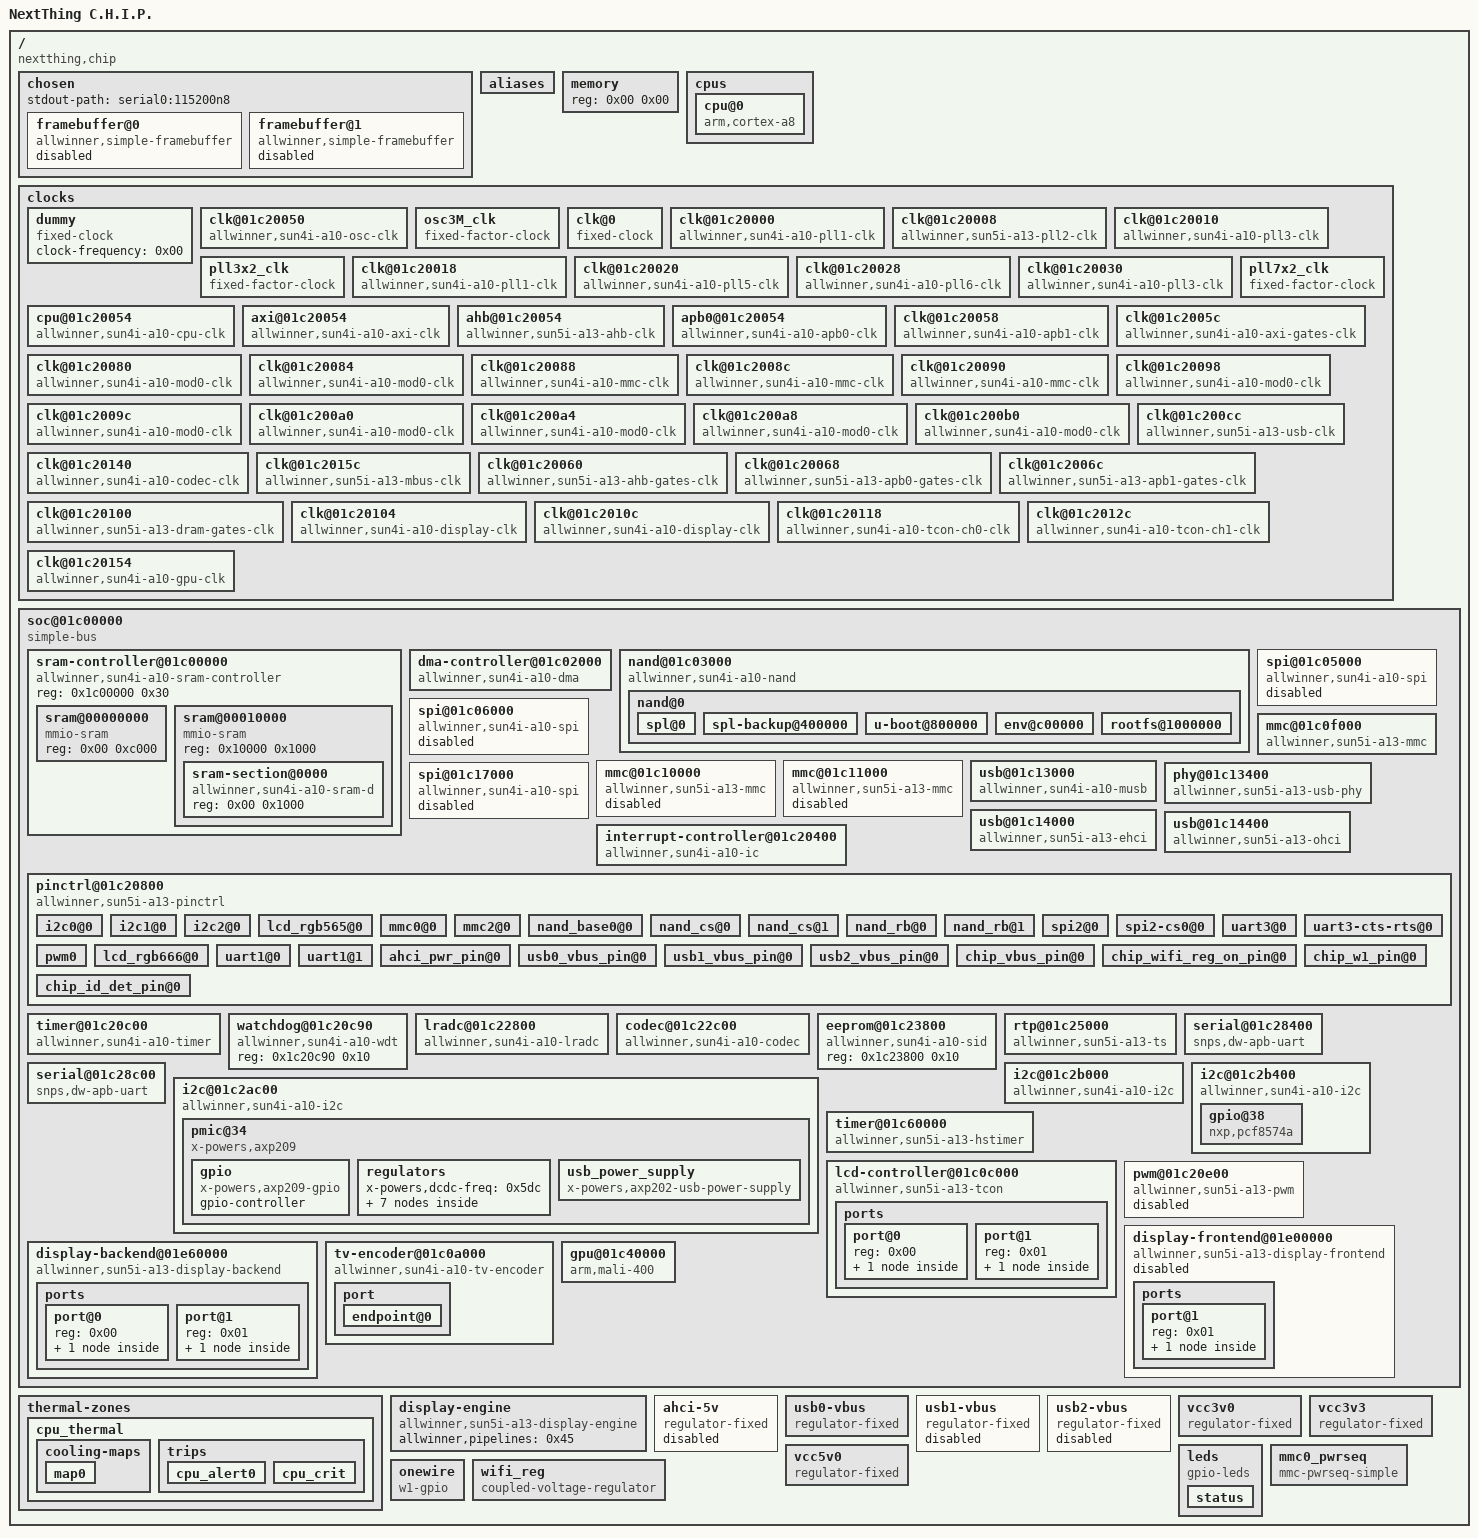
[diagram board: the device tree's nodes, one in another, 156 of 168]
/dts-v1/;

/ {
	#address-cells = <0x01>;
	#size-cells = <0x01>;
	interrupt-parent = <0x01>;
	model = "NextThing C.H.I.P.";
	compatible = "nextthing,chip", "allwinner,sun5i-r8";

	chosen {
		#address-cells = <0x01>;
		#size-cells = <0x01>;
		ranges;
		stdout-path = "serial0:115200n8";

		framebuffer@0 {
			compatible = "allwinner,simple-framebuffer", "simple-framebuffer";
			allwinner,pipeline = "de_be0-lcd0";
			clocks = <0x02 0x24 0x02 0x2c 0x03 0x04 0x05 0x1a>;
			status = "disabled";
		};

		framebuffer@1 {
			compatible = "allwinner,simple-framebuffer", "simple-framebuffer";
			allwinner,pipeline = "de_be0-lcd0-tve0";
			clocks = <0x02 0x22 0x02 0x24 0x02 0x2c 0x03 0x06 0x05 0x1a>;
			status = "disabled";
		};
	};

	aliases {
		i2c0 = "/soc@01c00000/i2c@01c2ac00";
		i2c1 = "/soc@01c00000/i2c@01c2b000";
		i2c2 = "/soc@01c00000/i2c@01c2b400";
		serial0 = "/soc@01c00000/serial@01c28400";
		serial1 = "/soc@01c00000/serial@01c28c00";
	};

	memory {
		device_type = "memory";
		reg = <0x00 0x00>;
	};

	cpus {
		#address-cells = <0x01>;
		#size-cells = <0x00>;

		cpu@0 {
			device_type = "cpu";
			compatible = "arm,cortex-a8";
			reg = <0x00>;
			clocks = <0x07>;
			clock-latency = <0x3b9b0>;
			operating-points = <0xf6180 0x155cc0 0xdea80 0x149970 0xd2f00 0x13d620 0x98580 0x124f80 0x8ca00 0x124f80 0x69780 0x124f80>;
			#cooling-cells = <0x02>;
			cooling-min-level = <0x00>;
			cooling-max-level = <0x05>;
			cpu-supply = <0x08>;
			linux,phandle = <0x44>;
			phandle = <0x44>;
		};
	};

	clocks {
		#address-cells = <0x01>;
		#size-cells = <0x01>;
		ranges;

		dummy {
			#clock-cells = <0x00>;
			compatible = "fixed-clock";
			clock-frequency = <0x00>;
			linux,phandle = <0x0f>;
			phandle = <0x0f>;
		};

		clk@01c20050 {
			#clock-cells = <0x00>;
			compatible = "allwinner,sun4i-a10-osc-clk";
			reg = <0x1c20050 0x04>;
			clock-frequency = <0x16e3600>;
			clock-output-names = "osc24M";
			linux,phandle = <0x09>;
			phandle = <0x09>;
		};

		osc3M_clk {
			compatible = "fixed-factor-clock";
			#clock-cells = <0x00>;
			clock-div = <0x08>;
			clock-mult = <0x01>;
			clocks = <0x09>;
			clock-output-names = "osc3M";
			linux,phandle = <0x0a>;
			phandle = <0x0a>;
		};

		clk@0 {
			#clock-cells = <0x00>;
			compatible = "fixed-clock";
			clock-frequency = <0x8000>;
			clock-output-names = "osc32k";
			linux,phandle = <0x0d>;
			phandle = <0x0d>;
		};

		clk@01c20000 {
			#clock-cells = <0x00>;
			compatible = "allwinner,sun4i-a10-pll1-clk";
			reg = <0x1c20000 0x04>;
			clocks = <0x09>;
			clock-output-names = "pll1";
			linux,phandle = <0x0e>;
			phandle = <0x0e>;
		};

		clk@01c20008 {
			#clock-cells = <0x01>;
			compatible = "allwinner,sun5i-a13-pll2-clk";
			reg = <0x1c20008 0x08>;
			clocks = <0x09>;
			clock-output-names = "pll2-1x", "pll2-2x", "pll2-4x", "pll2-8x";
			linux,phandle = <0x14>;
			phandle = <0x14>;
		};

		clk@01c20010 {
			#clock-cells = <0x00>;
			compatible = "allwinner,sun4i-a10-pll3-clk";
			reg = <0x1c20010 0x04>;
			clocks = <0x0a>;
			clock-output-names = "pll3";
			linux,phandle = <0x0b>;
			phandle = <0x0b>;
		};

		pll3x2_clk {
			compatible = "fixed-factor-clock";
			#clock-cells = <0x00>;
			clock-div = <0x01>;
			clock-mult = <0x02>;
			clocks = <0x0b>;
			clock-output-names = "pll3-2x";
			linux,phandle = <0x17>;
			phandle = <0x17>;
		};

		clk@01c20018 {
			#clock-cells = <0x00>;
			compatible = "allwinner,sun4i-a10-pll1-clk";
			reg = <0x1c20018 0x04>;
			clocks = <0x09>;
			clock-output-names = "pll4";
			linux,phandle = <0x19>;
			phandle = <0x19>;
		};

		clk@01c20020 {
			#clock-cells = <0x01>;
			compatible = "allwinner,sun4i-a10-pll5-clk";
			reg = <0x1c20020 0x04>;
			clocks = <0x09>;
			clock-output-names = "pll5_ddr", "pll5_other";
			linux,phandle = <0x13>;
			phandle = <0x13>;
		};

		clk@01c20028 {
			#clock-cells = <0x01>;
			compatible = "allwinner,sun4i-a10-pll6-clk";
			reg = <0x1c20028 0x04>;
			clocks = <0x09>;
			clock-output-names = "pll6_sata", "pll6_other", "pll6";
			linux,phandle = <0x11>;
			phandle = <0x11>;
		};

		clk@01c20030 {
			#clock-cells = <0x00>;
			compatible = "allwinner,sun4i-a10-pll3-clk";
			reg = <0x1c20030 0x04>;
			clocks = <0x0a>;
			clock-output-names = "pll7";
			linux,phandle = <0x0c>;
			phandle = <0x0c>;
		};

		pll7x2_clk {
			compatible = "fixed-factor-clock";
			#clock-cells = <0x00>;
			clock-div = <0x01>;
			clock-mult = <0x02>;
			clocks = <0x0c>;
			clock-output-names = "pll7-2x";
			linux,phandle = <0x18>;
			phandle = <0x18>;
		};

		cpu@01c20054 {
			#clock-cells = <0x00>;
			compatible = "allwinner,sun4i-a10-cpu-clk";
			reg = <0x1c20054 0x04>;
			clocks = <0x0d 0x09 0x0e 0x0f>;
			clock-output-names = "cpu";
			linux,phandle = <0x07>;
			phandle = <0x07>;
		};

		axi@01c20054 {
			#clock-cells = <0x00>;
			compatible = "allwinner,sun4i-a10-axi-clk";
			reg = <0x1c20054 0x04>;
			clocks = <0x07>;
			clock-output-names = "axi";
			linux,phandle = <0x10>;
			phandle = <0x10>;
		};

		ahb@01c20054 {
			#clock-cells = <0x00>;
			compatible = "allwinner,sun5i-a13-ahb-clk";
			reg = <0x1c20054 0x04>;
			clocks = <0x10 0x07 0x11 0x01>;
			clock-output-names = "ahb";
			assigned-clocks = <0x12>;
			assigned-clock-parents = <0x11 0x01>;
			linux,phandle = <0x12>;
			phandle = <0x12>;
		};

		apb0@01c20054 {
			#clock-cells = <0x00>;
			compatible = "allwinner,sun4i-a10-apb0-clk";
			reg = <0x1c20054 0x04>;
			clocks = <0x12>;
			clock-output-names = "apb0";
			linux,phandle = <0x15>;
			phandle = <0x15>;
		};

		clk@01c20058 {
			#clock-cells = <0x00>;
			compatible = "allwinner,sun4i-a10-apb1-clk";
			reg = <0x1c20058 0x04>;
			clocks = <0x09 0x11 0x01 0x0d>;
			clock-output-names = "apb1";
			linux,phandle = <0x16>;
			phandle = <0x16>;
		};

		clk@01c2005c {
			#clock-cells = <0x01>;
			compatible = "allwinner,sun4i-a10-axi-gates-clk";
			reg = <0x1c2005c 0x04>;
			clocks = <0x10>;
			clock-indices = <0x00>;
			clock-output-names = "axi_dram";
			linux,phandle = <0x4f>;
			phandle = <0x4f>;
		};

		clk@01c20080 {
			#clock-cells = <0x00>;
			compatible = "allwinner,sun4i-a10-mod0-clk";
			reg = <0x1c20080 0x04>;
			clocks = <0x09 0x11 0x01 0x13 0x01>;
			clock-output-names = "nand";
			linux,phandle = <0x1a>;
			phandle = <0x1a>;
		};

		clk@01c20084 {
			#clock-cells = <0x00>;
			compatible = "allwinner,sun4i-a10-mod0-clk";
			reg = <0x1c20084 0x04>;
			clocks = <0x09 0x11 0x01 0x13 0x01>;
			clock-output-names = "ms";
			linux,phandle = <0x50>;
			phandle = <0x50>;
		};

		clk@01c20088 {
			#clock-cells = <0x01>;
			compatible = "allwinner,sun4i-a10-mmc-clk";
			reg = <0x1c20088 0x04>;
			clocks = <0x09 0x11 0x01 0x13 0x01>;
			clock-output-names = "mmc0", "mmc0_output", "mmc0_sample";
			linux,phandle = <0x21>;
			phandle = <0x21>;
		};

		clk@01c2008c {
			#clock-cells = <0x01>;
			compatible = "allwinner,sun4i-a10-mmc-clk";
			reg = <0x1c2008c 0x04>;
			clocks = <0x09 0x11 0x01 0x13 0x01>;
			clock-output-names = "mmc1", "mmc1_output", "mmc1_sample";
			linux,phandle = <0x25>;
			phandle = <0x25>;
		};

		clk@01c20090 {
			#clock-cells = <0x01>;
			compatible = "allwinner,sun4i-a10-mmc-clk";
			reg = <0x1c20090 0x04>;
			clocks = <0x09 0x11 0x01 0x13 0x01>;
			clock-output-names = "mmc2", "mmc2_output", "mmc2_sample";
			linux,phandle = <0x26>;
			phandle = <0x26>;
		};

		clk@01c20098 {
			#clock-cells = <0x00>;
			compatible = "allwinner,sun4i-a10-mod0-clk";
			reg = <0x1c20098 0x04>;
			clocks = <0x09 0x11 0x01 0x13 0x01>;
			clock-output-names = "ts";
			linux,phandle = <0x51>;
			phandle = <0x51>;
		};

		clk@01c2009c {
			#clock-cells = <0x00>;
			compatible = "allwinner,sun4i-a10-mod0-clk";
			reg = <0x1c2009c 0x04>;
			clocks = <0x09 0x11 0x01 0x13 0x01>;
			clock-output-names = "ss";
			linux,phandle = <0x52>;
			phandle = <0x52>;
		};

		clk@01c200a0 {
			#clock-cells = <0x00>;
			compatible = "allwinner,sun4i-a10-mod0-clk";
			reg = <0x1c200a0 0x04>;
			clocks = <0x09 0x11 0x01 0x13 0x01>;
			clock-output-names = "spi0";
			linux,phandle = <0x1f>;
			phandle = <0x1f>;
		};

		clk@01c200a4 {
			#clock-cells = <0x00>;
			compatible = "allwinner,sun4i-a10-mod0-clk";
			reg = <0x1c200a4 0x04>;
			clocks = <0x09 0x11 0x01 0x13 0x01>;
			clock-output-names = "spi1";
			linux,phandle = <0x20>;
			phandle = <0x20>;
		};

		clk@01c200a8 {
			#clock-cells = <0x00>;
			compatible = "allwinner,sun4i-a10-mod0-clk";
			reg = <0x1c200a8 0x04>;
			clocks = <0x09 0x11 0x01 0x13 0x01>;
			clock-output-names = "spi2";
			linux,phandle = <0x2f>;
			phandle = <0x2f>;
		};

		clk@01c200b0 {
			#clock-cells = <0x00>;
			compatible = "allwinner,sun4i-a10-mod0-clk";
			reg = <0x1c200b0 0x04>;
			clocks = <0x09 0x11 0x01 0x13 0x01>;
			clock-output-names = "ir0";
			linux,phandle = <0x53>;
			phandle = <0x53>;
		};

		clk@01c200cc {
			#clock-cells = <0x01>;
			#reset-cells = <0x01>;
			compatible = "allwinner,sun5i-a13-usb-clk";
			reg = <0x1c200cc 0x04>;
			clocks = <0x11 0x01>;
			clock-output-names = "usb_ohci0", "usb_phy";
			linux,phandle = <0x29>;
			phandle = <0x29>;
		};

		clk@01c20140 {
			#clock-cells = <0x00>;
			compatible = "allwinner,sun4i-a10-codec-clk";
			reg = <0x1c20140 0x04>;
			clocks = <0x14 0x00>;
			clock-output-names = "codec";
			linux,phandle = <0x32>;
			phandle = <0x32>;
		};

		clk@01c2015c {
			#clock-cells = <0x00>;
			compatible = "allwinner,sun5i-a13-mbus-clk";
			reg = <0x1c2015c 0x04>;
			clocks = <0x09 0x11 0x01 0x13 0x01>;
			clock-output-names = "mbus";
			linux,phandle = <0x54>;
			phandle = <0x54>;
		};

		clk@01c20060 {
			#clock-cells = <0x01>;
			compatible = "allwinner,sun5i-a13-ahb-gates-clk";
			reg = <0x1c20060 0x08>;
			clocks = <0x12>;
			clock-indices = <0x00 0x01 0x02 0x05 0x06 0x07 0x08 0x09 0x0a 0x0d 0x0e 0x14 0x15 0x16 0x1c 0x20 0x22 0x24 0x28 0x2c 0x2e 0x33 0x34>;
			clock-output-names = "ahb_usbotg", "ahb_ehci", "ahb_ohci", "ahb_ss", "ahb_dma", "ahb_bist", "ahb_mmc0", "ahb_mmc1", "ahb_mmc2", "ahb_nand", "ahb_sdram", "ahb_spi0", "ahb_spi1", "ahb_spi2", "ahb_stimer", "ahb_ve", "ahb_tve", "ahb_lcd", "ahb_csi", "ahb_de_be", "ahb_de_fe", "ahb_iep", "ahb_mali400";
			linux,phandle = <0x02>;
			phandle = <0x02>;
		};

		clk@01c20068 {
			#clock-cells = <0x01>;
			compatible = "allwinner,sun5i-a13-apb0-gates-clk";
			reg = <0x1c20068 0x04>;
			clocks = <0x15>;
			clock-indices = <0x00 0x05 0x06>;
			clock-output-names = "apb0_codec", "apb0_pio", "apb0_ir";
			linux,phandle = <0x30>;
			phandle = <0x30>;
		};

		clk@01c2006c {
			#clock-cells = <0x01>;
			compatible = "allwinner,sun5i-a13-apb1-gates-clk";
			reg = <0x1c2006c 0x04>;
			clocks = <0x16>;
			clock-indices = <0x00 0x01 0x02 0x11 0x13>;
			clock-output-names = "apb1_i2c0", "apb1_i2c1", "apb1_i2c2", "apb1_uart1", "apb1_uart3";
			linux,phandle = <0x33>;
			phandle = <0x33>;
		};

		clk@01c20100 {
			#clock-cells = <0x01>;
			compatible = "allwinner,sun5i-a13-dram-gates-clk", "allwinner,sun4i-a10-gates-clk";
			reg = <0x1c20100 0x04>;
			clocks = <0x13 0x00>;
			clock-indices = <0x00 0x01 0x19 0x1a 0x1d 0x1f>;
			clock-output-names = "dram_ve", "dram_csi", "dram_de_fe", "dram_de_be", "dram_ace", "dram_iep";
			linux,phandle = <0x05>;
			phandle = <0x05>;
		};

		clk@01c20104 {
			#clock-cells = <0x00>;
			#reset-cells = <0x00>;
			compatible = "allwinner,sun4i-a10-display-clk";
			reg = <0x1c20104 0x04>;
			clocks = <0x0b 0x0c 0x13 0x01>;
			clock-output-names = "de-be";
			linux,phandle = <0x03>;
			phandle = <0x03>;
		};

		clk@01c2010c {
			#clock-cells = <0x00>;
			#reset-cells = <0x00>;
			compatible = "allwinner,sun4i-a10-display-clk";
			reg = <0x1c2010c 0x04>;
			clocks = <0x0b 0x0c 0x13 0x01>;
			clock-output-names = "de-fe";
			linux,phandle = <0x3c>;
			phandle = <0x3c>;
		};

		clk@01c20118 {
			#clock-cells = <0x00>;
			#reset-cells = <0x01>;
			compatible = "allwinner,sun4i-a10-tcon-ch0-clk";
			reg = <0x1c20118 0x04>;
			clocks = <0x0b 0x0c 0x17 0x18>;
			clock-output-names = "tcon-ch0-sclk";
			linux,phandle = <0x04>;
			phandle = <0x04>;
		};

		clk@01c2012c {
			#clock-cells = <0x00>;
			compatible = "allwinner,sun4i-a10-tcon-ch1-clk";
			reg = <0x1c2012c 0x04>;
			clocks = <0x0b 0x0c 0x17 0x18>;
			clock-output-names = "tcon-ch1-sclk";
			linux,phandle = <0x06>;
			phandle = <0x06>;
		};

		clk@01c20154 {
			#clock-cells = <0x00>;
			#reset-cells = <0x00>;
			compatible = "allwinner,sun4i-a10-gpu-clk";
			reg = <0x1c20154 0x04>;
			clocks = <0x0b 0x19 0x13 0x01 0x0c 0x18>;
			clock-output-names = "mali";
			linux,phandle = <0x41>;
			phandle = <0x41>;
		};
	};

	soc@01c00000 {
		compatible = "simple-bus";
		#address-cells = <0x01>;
		#size-cells = <0x01>;
		ranges;

		sram-controller@01c00000 {
			compatible = "allwinner,sun4i-a10-sram-controller";
			reg = <0x1c00000 0x30>;
			#address-cells = <0x01>;
			#size-cells = <0x01>;
			ranges;

			sram@00000000 {
				compatible = "mmio-sram";
				reg = <0x00 0xc000>;
				#address-cells = <0x01>;
				#size-cells = <0x01>;
				ranges = <0x00 0x00 0xc000>;
				linux,phandle = <0x55>;
				phandle = <0x55>;
			};

			sram@00010000 {
				compatible = "mmio-sram";
				reg = <0x10000 0x1000>;
				#address-cells = <0x01>;
				#size-cells = <0x01>;
				ranges = <0x00 0x10000 0x1000>;
				linux,phandle = <0x56>;
				phandle = <0x56>;

				sram-section@0000 {
					compatible = "allwinner,sun4i-a10-sram-d";
					reg = <0x00 0x1000>;
					status = "okay";
					linux,phandle = <0x28>;
					phandle = <0x28>;
				};
			};
		};

		dma-controller@01c02000 {
			compatible = "allwinner,sun4i-a10-dma";
			reg = <0x1c02000 0x1000>;
			interrupts = <0x1b>;
			clocks = <0x02 0x06>;
			#dma-cells = <0x02>;
			linux,phandle = <0x1e>;
			phandle = <0x1e>;
		};

		nand@01c03000 {
			compatible = "allwinner,sun4i-a10-nand";
			reg = <0x1c03000 0x1000>;
			interrupts = <0x25>;
			clocks = <0x02 0x0d 0x1a>;
			clock-names = "ahb", "mod";
			#address-cells = <0x01>;
			#size-cells = <0x00>;
			status = "okay";
			pinctrl-names = "default";
			pinctrl-0 = <0x1b 0x1c 0x1d>;
			dmas = <0x1e 0x01 0x03>;
			dma-names = "rxtx";
			linux,phandle = <0x57>;
			phandle = <0x57>;

			nand@0 {
				#address-cells = <0x02>;
				#size-cells = <0x02>;
				reg = <0x00>;
				allwinner,rb = <0x00>;
				nand-ecc-mode = "hw";

				spl@0 {
					label = "SPL";
					reg = <0x00 0x00 0x00 0x400000>;
				};

				spl-backup@400000 {
					label = "SPL.backup";
					reg = <0x00 0x400000 0x00 0x400000>;
				};

				u-boot@800000 {
					label = "U-Boot";
					reg = <0x00 0x800000 0x00 0x400000>;
				};

				env@c00000 {
					label = "env";
					reg = <0x00 0xc00000 0x00 0x400000>;
				};

				rootfs@1000000 {
					label = "rootfs";
					reg = <0x00 0x1000000 0x01 0xff000000>;
				};
			};
		};

		spi@01c05000 {
			compatible = "allwinner,sun4i-a10-spi";
			reg = <0x1c05000 0x1000>;
			interrupts = <0x0a>;
			clocks = <0x02 0x14 0x1f>;
			clock-names = "ahb", "mod";
			dmas = <0x1e 0x01 0x1b 0x1e 0x01 0x1a>;
			dma-names = "rx", "tx";
			status = "disabled";
			#address-cells = <0x01>;
			#size-cells = <0x00>;
			linux,phandle = <0x58>;
			phandle = <0x58>;
		};

		spi@01c06000 {
			compatible = "allwinner,sun4i-a10-spi";
			reg = <0x1c06000 0x1000>;
			interrupts = <0x0b>;
			clocks = <0x02 0x15 0x20>;
			clock-names = "ahb", "mod";
			dmas = <0x1e 0x01 0x09 0x1e 0x01 0x08>;
			dma-names = "rx", "tx";
			status = "disabled";
			#address-cells = <0x01>;
			#size-cells = <0x00>;
			linux,phandle = <0x59>;
			phandle = <0x59>;
		};

		mmc@01c0f000 {
			compatible = "allwinner,sun5i-a13-mmc";
			reg = <0x1c0f000 0x1000>;
			clocks = <0x02 0x08 0x21 0x00 0x21 0x01 0x21 0x02>;
			clock-names = "ahb", "mmc", "output", "sample";
			interrupts = <0x20>;
			status = "okay";
			#address-cells = <0x01>;
			#size-cells = <0x00>;
			pinctrl-names = "default";
			pinctrl-0 = <0x22>;
			vmmc-supply = <0x23>;
			mmc-pwrseq = <0x24>;
			bus-width = <0x04>;
			non-removable;
			linux,phandle = <0x5a>;
			phandle = <0x5a>;
		};

		mmc@01c10000 {
			compatible = "allwinner,sun5i-a13-mmc";
			reg = <0x1c10000 0x1000>;
			clocks = <0x02 0x09 0x25 0x00 0x25 0x01 0x25 0x02>;
			clock-names = "ahb", "mmc", "output", "sample";
			interrupts = <0x21>;
			status = "disabled";
			#address-cells = <0x01>;
			#size-cells = <0x00>;
			linux,phandle = <0x5b>;
			phandle = <0x5b>;
		};

		mmc@01c11000 {
			compatible = "allwinner,sun5i-a13-mmc";
			reg = <0x1c11000 0x1000>;
			clocks = <0x02 0x0a 0x26 0x00 0x26 0x01 0x26 0x02>;
			clock-names = "ahb", "mmc", "output", "sample";
			interrupts = <0x22>;
			status = "disabled";
			#address-cells = <0x01>;
			#size-cells = <0x00>;
			linux,phandle = <0x5c>;
			phandle = <0x5c>;
		};

		usb@01c13000 {
			compatible = "allwinner,sun4i-a10-musb";
			reg = <0x1c13000 0x400>;
			clocks = <0x02 0x00>;
			interrupts = <0x26>;
			interrupt-names = "mc";
			phys = <0x27 0x00>;
			phy-names = "usb";
			extcon = <0x27 0x00>;
			allwinner,sram = <0x28 0x01>;
			status = "okay";
			dr_mode = "otg";
			linux,phandle = <0x5d>;
			phandle = <0x5d>;
		};

		phy@01c13400 {
			#phy-cells = <0x01>;
			compatible = "allwinner,sun5i-a13-usb-phy";
			reg = <0x1c13400 0x10 0x1c14800 0x04>;
			reg-names = "phy_ctrl", "pmu1";
			clocks = <0x29 0x08>;
			clock-names = "usb_phy";
			resets = <0x29 0x00 0x29 0x01>;
			reset-names = "usb0_reset", "usb1_reset";
			status = "okay";
			pinctrl-names = "default";
			pinctrl-0 = <0x2a>;
			usb0_id_det-gpio = <0x2b 0x06 0x02 0x00>;
			usb0_vbus_power-supply = <0x2c>;
			usb0_vbus-supply = <0x2d>;
			usb1_vbus-supply = <0x2e>;
			linux,phandle = <0x27>;
			phandle = <0x27>;
		};

		usb@01c14000 {
			compatible = "allwinner,sun5i-a13-ehci", "generic-ehci";
			reg = <0x1c14000 0x100>;
			interrupts = <0x27>;
			clocks = <0x02 0x01>;
			phys = <0x27 0x01>;
			phy-names = "usb";
			status = "okay";
			linux,phandle = <0x5e>;
			phandle = <0x5e>;
		};

		usb@01c14400 {
			compatible = "allwinner,sun5i-a13-ohci", "generic-ohci";
			reg = <0x1c14400 0x100>;
			interrupts = <0x28>;
			clocks = <0x29 0x06 0x02 0x02>;
			phys = <0x27 0x01>;
			phy-names = "usb";
			status = "okay";
			linux,phandle = <0x5f>;
			phandle = <0x5f>;
		};

		spi@01c17000 {
			compatible = "allwinner,sun4i-a10-spi";
			reg = <0x1c17000 0x1000>;
			interrupts = <0x0c>;
			clocks = <0x02 0x16 0x2f>;
			clock-names = "ahb", "mod";
			dmas = <0x1e 0x01 0x1d 0x1e 0x01 0x1c>;
			dma-names = "rx", "tx";
			status = "disabled";
			#address-cells = <0x01>;
			#size-cells = <0x00>;
			linux,phandle = <0x60>;
			phandle = <0x60>;
		};

		interrupt-controller@01c20400 {
			compatible = "allwinner,sun4i-a10-ic";
			reg = <0x1c20400 0x400>;
			interrupt-controller;
			#interrupt-cells = <0x01>;
			linux,phandle = <0x01>;
			phandle = <0x01>;
		};

		pinctrl@01c20800 {
			reg = <0x1c20800 0x400>;
			interrupts = <0x1c>;
			clocks = <0x30 0x05>;
			gpio-controller;
			interrupt-controller;
			#interrupt-cells = <0x03>;
			#gpio-cells = <0x03>;
			compatible = "allwinner,sun5i-a13-pinctrl";
			linux,phandle = <0x2b>;
			phandle = <0x2b>;

			i2c0@0 {
				allwinner,pins = "PB0", "PB1";
				allwinner,function = "i2c0";
				allwinner,drive = <0x00>;
				allwinner,pull = <0x00>;
				linux,phandle = <0x37>;
				phandle = <0x37>;
			};

			i2c1@0 {
				allwinner,pins = "PB15", "PB16";
				allwinner,function = "i2c1";
				allwinner,drive = <0x00>;
				allwinner,pull = <0x00>;
				linux,phandle = <0x38>;
				phandle = <0x38>;
			};

			i2c2@0 {
				allwinner,pins = "PB17", "PB18";
				allwinner,function = "i2c2";
				allwinner,drive = <0x00>;
				allwinner,pull = <0x00>;
				linux,phandle = <0x39>;
				phandle = <0x39>;
			};

			lcd_rgb565@0 {
				allwinner,pins = "PD3", "PD4", "PD5", "PD6", "PD7", "PD10", "PD11", "PD12", "PD13", "PD14", "PD15", "PD19", "PD20", "PD21", "PD22", "PD23", "PD24", "PD25", "PD26", "PD27";
				allwinner,function = "lcd0";
				allwinner,drive = <0x00>;
				allwinner,pull = <0x00>;
				linux,phandle = <0x61>;
				phandle = <0x61>;
			};

			mmc0@0 {
				allwinner,pins = "PF0", "PF1", "PF2", "PF3", "PF4", "PF5";
				allwinner,function = "mmc0";
				allwinner,drive = <0x02>;
				allwinner,pull = <0x01>;
				linux,phandle = <0x22>;
				phandle = <0x22>;
			};

			mmc2@0 {
				allwinner,pins = "PC6", "PC7", "PC8", "PC9", "PC10", "PC11", "PC12", "PC13", "PC14", "PC15";
				allwinner,function = "mmc2";
				allwinner,drive = <0x02>;
				allwinner,pull = <0x01>;
				linux,phandle = <0x62>;
				phandle = <0x62>;
			};

			nand_base0@0 {
				allwinner,pins = "PC0", "PC1", "PC2", "PC5", "PC8", "PC9", "PC10", "PC11", "PC12", "PC13", "PC14", "PC15";
				allwinner,function = "nand0";
				allwinner,drive = <0x00>;
				allwinner,pull = <0x00>;
				linux,phandle = <0x1b>;
				phandle = <0x1b>;
			};

			nand_cs@0 {
				allwinner,pins = "PC4";
				allwinner,function = "nand0";
				allwinner,drive = <0x00>;
				allwinner,pull = <0x00>;
				linux,phandle = <0x1c>;
				phandle = <0x1c>;
			};

			nand_cs@1 {
				allwinner,pins = "PC3";
				allwinner,function = "nand0";
				allwinner,drive = <0x00>;
				allwinner,pull = <0x00>;
				linux,phandle = <0x63>;
				phandle = <0x63>;
			};

			nand_rb@0 {
				allwinner,pins = "PC6";
				allwinner,function = "nand0";
				allwinner,drive = <0x00>;
				allwinner,pull = <0x00>;
				linux,phandle = <0x1d>;
				phandle = <0x1d>;
			};

			nand_rb@1 {
				allwinner,pins = "PC7";
				allwinner,function = "nand0";
				allwinner,drive = <0x00>;
				allwinner,pull = <0x00>;
				linux,phandle = <0x64>;
				phandle = <0x64>;
			};

			spi2@0 {
				allwinner,pins = "PE1", "PE2", "PE3";
				allwinner,function = "spi2";
				allwinner,drive = <0x00>;
				allwinner,pull = <0x00>;
				linux,phandle = <0x65>;
				phandle = <0x65>;
			};

			spi2-cs0@0 {
				allwinner,pins = "PE0";
				allwinner,function = "spi2";
				allwinner,drive = <0x00>;
				allwinner,pull = <0x00>;
				linux,phandle = <0x66>;
				phandle = <0x66>;
			};

			uart3@0 {
				allwinner,pins = "PG9", "PG10";
				allwinner,function = "uart3";
				allwinner,drive = <0x00>;
				allwinner,pull = <0x00>;
				linux,phandle = <0x35>;
				phandle = <0x35>;
			};

			uart3-cts-rts@0 {
				allwinner,pins = "PG11", "PG12";
				allwinner,function = "uart3";
				allwinner,drive = <0x00>;
				allwinner,pull = <0x00>;
				linux,phandle = <0x36>;
				phandle = <0x36>;
			};

			pwm0 {
				allwinner,pins = "PB2";
				allwinner,function = "pwm";
				allwinner,drive = <0x00>;
				allwinner,pull = <0x00>;
				linux,phandle = <0x67>;
				phandle = <0x67>;
			};

			lcd_rgb666@0 {
				allwinner,pins = "PD2", "PD3", "PD4", "PD5", "PD6", "PD7", "PD10", "PD11", "PD12", "PD13", "PD14", "PD15", "PD18", "PD19", "PD20", "PD21", "PD22", "PD23", "PD24", "PD25", "PD26", "PD27";
				allwinner,function = "lcd0";
				allwinner,drive = <0x00>;
				allwinner,pull = <0x00>;
				linux,phandle = <0x68>;
				phandle = <0x68>;
			};

			uart1@0 {
				allwinner,pins = "PE10", "PE11";
				allwinner,function = "uart1";
				allwinner,drive = <0x00>;
				allwinner,pull = <0x00>;
				linux,phandle = <0x69>;
				phandle = <0x69>;
			};

			uart1@1 {
				allwinner,pins = "PG3", "PG4";
				allwinner,function = "uart1";
				allwinner,drive = <0x00>;
				allwinner,pull = <0x00>;
				linux,phandle = <0x34>;
				phandle = <0x34>;
			};

			ahci_pwr_pin@0 {
				allwinner,pins = "PB8";
				allwinner,function = "gpio_out";
				allwinner,drive = <0x00>;
				allwinner,pull = <0x00>;
				linux,phandle = <0x46>;
				phandle = <0x46>;
			};

			usb0_vbus_pin@0 {
				allwinner,pins = "PB9";
				allwinner,function = "gpio_out";
				allwinner,drive = <0x00>;
				allwinner,pull = <0x00>;
				linux,phandle = <0x6a>;
				phandle = <0x6a>;
			};

			usb1_vbus_pin@0 {
				allwinner,pins = "PH6";
				allwinner,function = "gpio_out";
				allwinner,drive = <0x00>;
				allwinner,pull = <0x00>;
				linux,phandle = <0x48>;
				phandle = <0x48>;
			};

			usb2_vbus_pin@0 {
				allwinner,pins = "PH3";
				allwinner,function = "gpio_out";
				allwinner,drive = <0x00>;
				allwinner,pull = <0x00>;
				linux,phandle = <0x49>;
				phandle = <0x49>;
			};

			chip_vbus_pin@0 {
				allwinner,pins = "PB10";
				allwinner,function = "gpio_out";
				allwinner,drive = <0x00>;
				allwinner,pull = <0x00>;
				linux,phandle = <0x47>;
				phandle = <0x47>;
			};

			chip_wifi_reg_on_pin@0 {
				allwinner,pins = "PC19";
				allwinner,function = "gpio_out";
				allwinner,drive = <0x00>;
				allwinner,pull = <0x00>;
				linux,phandle = <0x4b>;
				phandle = <0x4b>;
			};

			chip_id_det_pin@0 {
				allwinner,pins = "PG2";
				allwinner,function = "gpio_in";
				allwinner,drive = <0x00>;
				allwinner,pull = <0x00>;
				linux,phandle = <0x2a>;
				phandle = <0x2a>;
			};

			chip_w1_pin@0 {
				allwinner,pins = "PD2";
				allwinner,function = "gpio_in";
				allwinner,drive = <0x00>;
				allwinner,pull = <0x01>;
				linux,phandle = <0x4c>;
				phandle = <0x4c>;
			};
		};

		timer@01c20c00 {
			compatible = "allwinner,sun4i-a10-timer";
			reg = <0x1c20c00 0x90>;
			interrupts = <0x16>;
			clocks = <0x09>;
		};

		watchdog@01c20c90 {
			compatible = "allwinner,sun4i-a10-wdt";
			reg = <0x1c20c90 0x10>;
			linux,phandle = <0x6b>;
			phandle = <0x6b>;
		};

		lradc@01c22800 {
			#io-channel-cells = <0x01>;
			compatible = "allwinner,sun4i-a10-lradc";
			reg = <0x1c22800 0x100>;
			interrupts = <0x1f>;
			status = "okay";
			vref-supply = <0x31>;
			linux,phandle = <0x6c>;
			phandle = <0x6c>;
		};

		codec@01c22c00 {
			#sound-dai-cells = <0x00>;
			compatible = "allwinner,sun4i-a10-codec";
			reg = <0x1c22c00 0x40>;
			interrupts = <0x1e>;
			clocks = <0x30 0x00 0x32>;
			clock-names = "apb", "codec";
			dmas = <0x1e 0x00 0x13 0x1e 0x00 0x13>;
			dma-names = "rx", "tx";
			status = "okay";
			linux,phandle = <0x6d>;
			phandle = <0x6d>;
		};

		eeprom@01c23800 {
			compatible = "allwinner,sun4i-a10-sid";
			reg = <0x1c23800 0x10>;
			linux,phandle = <0x6e>;
			phandle = <0x6e>;
		};

		rtp@01c25000 {
			compatible = "allwinner,sun5i-a13-ts";
			reg = <0x1c25000 0x100>;
			interrupts = <0x1d>;
			#thermal-sensor-cells = <0x00>;
			linux,phandle = <0x42>;
			phandle = <0x42>;
		};

		serial@01c28400 {
			compatible = "snps,dw-apb-uart";
			reg = <0x1c28400 0x400>;
			interrupts = <0x02>;
			reg-shift = <0x02>;
			reg-io-width = <0x04>;
			clocks = <0x33 0x11>;
			status = "okay";
			pinctrl-names = "default";
			pinctrl-0 = <0x34>;
			linux,phandle = <0x6f>;
			phandle = <0x6f>;
		};

		serial@01c28c00 {
			compatible = "snps,dw-apb-uart";
			reg = <0x1c28c00 0x400>;
			interrupts = <0x04>;
			reg-shift = <0x02>;
			reg-io-width = <0x04>;
			clocks = <0x33 0x13>;
			status = "okay";
			pinctrl-names = "default";
			pinctrl-0 = <0x35 0x36>;
			linux,phandle = <0x70>;
			phandle = <0x70>;
		};

		i2c@01c2ac00 {
			compatible = "allwinner,sun4i-a10-i2c";
			reg = <0x1c2ac00 0x400>;
			interrupts = <0x07>;
			clocks = <0x33 0x00>;
			status = "okay";
			#address-cells = <0x01>;
			#size-cells = <0x00>;
			pinctrl-names = "default";
			pinctrl-0 = <0x37>;
			linux,phandle = <0x71>;
			phandle = <0x71>;

			pmic@34 {
				reg = <0x34>;
				interrupts = <0x00>;
				compatible = "x-powers,axp209";
				interrupt-controller;
				#interrupt-cells = <0x01>;
				linux,phandle = <0x72>;
				phandle = <0x72>;

				gpio {
					compatible = "x-powers,axp209-gpio";
					gpio-controller;
					#gpio-cells = <0x02>;
					linux,phandle = <0x4a>;
					phandle = <0x4a>;
				};

				regulators {
					x-powers,dcdc-freq = <0x5dc>;

					dcdc2 {
						regulator-name = "cpuvdd";
						regulator-min-microvolt = <0xf4240>;
						regulator-max-microvolt = <0x155cc0>;
						regulator-always-on;
						linux,phandle = <0x08>;
						phandle = <0x08>;
					};

					dcdc3 {
						regulator-name = "corevdd";
						regulator-min-microvolt = <0xf4240>;
						regulator-max-microvolt = <0x13d620>;
						regulator-always-on;
						linux,phandle = <0x73>;
						phandle = <0x73>;
					};

					ldo1 {
						regulator-always-on;
						regulator-min-microvolt = <0x13d620>;
						regulator-max-microvolt = <0x13d620>;
						regulator-name = "rtcvdd";
						linux,phandle = <0x74>;
						phandle = <0x74>;
					};

					ldo2 {
						regulator-name = "avcc";
						regulator-min-microvolt = <0x2932e0>;
						regulator-max-microvolt = <0x325aa0>;
						regulator-always-on;
						linux,phandle = <0x75>;
						phandle = <0x75>;
					};

					ldo3 {
						regulator-name = "vcc-wifi-1";
						regulator-min-microvolt = <0x325aa0>;
						regulator-max-microvolt = <0x325aa0>;
						linux,phandle = <0x4d>;
						phandle = <0x4d>;
					};

					ldo4 {
						regulator-name = "vcc-wifi-2";
						regulator-min-microvolt = <0x325aa0>;
						regulator-max-microvolt = <0x325aa0>;
						linux,phandle = <0x4e>;
						phandle = <0x4e>;
					};

					ldo5 {
						regulator-name = "vcc-1v8";
						regulator-min-microvolt = <0x1b7740>;
						regulator-max-microvolt = <0x1b7740>;
						linux,phandle = <0x76>;
						phandle = <0x76>;
					};
				};

				usb_power_supply {
					compatible = "x-powers,axp202-usb-power-supply";
					status = "okay";
					linux,phandle = <0x2c>;
					phandle = <0x2c>;
				};
			};
		};

		i2c@01c2b000 {
			compatible = "allwinner,sun4i-a10-i2c";
			reg = <0x1c2b000 0x400>;
			interrupts = <0x08>;
			clocks = <0x33 0x01>;
			status = "okay";
			#address-cells = <0x01>;
			#size-cells = <0x00>;
			pinctrl-names = "default";
			pinctrl-0 = <0x38>;
			linux,phandle = <0x77>;
			phandle = <0x77>;
		};

		i2c@01c2b400 {
			compatible = "allwinner,sun4i-a10-i2c";
			reg = <0x1c2b400 0x400>;
			interrupts = <0x09>;
			clocks = <0x33 0x02>;
			status = "okay";
			#address-cells = <0x01>;
			#size-cells = <0x00>;
			pinctrl-names = "default";
			pinctrl-0 = <0x39>;
			linux,phandle = <0x78>;
			phandle = <0x78>;

			gpio@38 {
				compatible = "nxp,pcf8574a";
				reg = <0x38>;
				gpio-controller;
				#gpio-cells = <0x02>;
				interrupt-parent = <0x2b>;
				interrupts = <0x06 0x00 0x02>;
				interrupt-controller;
				#interrupt-cells = <0x02>;
				linux,phandle = <0x79>;
				phandle = <0x79>;
			};
		};

		timer@01c60000 {
			compatible = "allwinner,sun5i-a13-hstimer";
			reg = <0x1c60000 0x1000>;
			interrupts = <0x52 0x53>;
			clocks = <0x02 0x1c>;
		};

		lcd-controller@01c0c000 {
			compatible = "allwinner,sun5i-a13-tcon";
			reg = <0x1c0c000 0x1000>;
			interrupts = <0x2c>;
			resets = <0x04 0x01>;
			reset-names = "lcd";
			clocks = <0x02 0x24 0x04 0x06>;
			clock-names = "ahb", "tcon-ch0", "tcon-ch1";
			clock-output-names = "tcon-pixel-clock";
			status = "okay";
			linux,phandle = <0x7a>;
			phandle = <0x7a>;

			ports {
				#address-cells = <0x01>;
				#size-cells = <0x00>;

				port@0 {
					#address-cells = <0x01>;
					#size-cells = <0x00>;
					reg = <0x00>;
					linux,phandle = <0x7b>;
					phandle = <0x7b>;

					endpoint@0 {
						reg = <0x00>;
						remote-endpoint = <0x3a>;
						linux,phandle = <0x3f>;
						phandle = <0x3f>;
					};
				};

				port@1 {
					#address-cells = <0x01>;
					#size-cells = <0x00>;
					reg = <0x01>;
					linux,phandle = <0x7c>;
					phandle = <0x7c>;

					endpoint@1 {
						reg = <0x01>;
						remote-endpoint = <0x3b>;
						linux,phandle = <0x40>;
						phandle = <0x40>;
					};
				};
			};
		};

		pwm@01c20e00 {
			compatible = "allwinner,sun5i-a13-pwm";
			reg = <0x1c20e00 0x0c>;
			clocks = <0x09>;
			#pwm-cells = <0x03>;
			status = "disabled";
			linux,phandle = <0x7d>;
			phandle = <0x7d>;
		};

		display-frontend@01e00000 {
			compatible = "allwinner,sun5i-a13-display-frontend";
			reg = <0x1e00000 0x20000>;
			interrupts = <0x2f>;
			clocks = <0x02 0x2e 0x3c 0x05 0x19>;
			clock-names = "ahb", "mod", "ram";
			resets = <0x3c>;
			status = "disabled";
			linux,phandle = <0x45>;
			phandle = <0x45>;

			ports {
				#address-cells = <0x01>;
				#size-cells = <0x00>;

				port@1 {
					#address-cells = <0x01>;
					#size-cells = <0x00>;
					reg = <0x01>;
					linux,phandle = <0x7e>;
					phandle = <0x7e>;

					endpoint@0 {
						reg = <0x00>;
						remote-endpoint = <0x3d>;
						linux,phandle = <0x3e>;
						phandle = <0x3e>;
					};
				};
			};
		};

		display-backend@01e60000 {
			compatible = "allwinner,sun5i-a13-display-backend";
			reg = <0x1e60000 0x10000>;
			clocks = <0x02 0x2c 0x03 0x05 0x1a>;
			clock-names = "ahb", "mod", "ram";
			resets = <0x03>;
			status = "okay";
			assigned-clocks = <0x03>;
			assigned-clock-rates = <0x11e1a300>;
			linux,phandle = <0x7f>;
			phandle = <0x7f>;

			ports {
				#address-cells = <0x01>;
				#size-cells = <0x00>;

				port@0 {
					#address-cells = <0x01>;
					#size-cells = <0x00>;
					reg = <0x00>;
					linux,phandle = <0x80>;
					phandle = <0x80>;

					endpoint@0 {
						reg = <0x00>;
						remote-endpoint = <0x3e>;
						linux,phandle = <0x3d>;
						phandle = <0x3d>;
					};
				};

				port@1 {
					#address-cells = <0x01>;
					#size-cells = <0x00>;
					reg = <0x01>;
					linux,phandle = <0x81>;
					phandle = <0x81>;

					endpoint@0 {
						reg = <0x00>;
						remote-endpoint = <0x3f>;
						linux,phandle = <0x3a>;
						phandle = <0x3a>;
					};
				};
			};
		};

		tv-encoder@01c0a000 {
			compatible = "allwinner,sun4i-a10-tv-encoder";
			reg = <0x1c0a000 0x1000>;
			clocks = <0x02 0x22>;
			resets = <0x04 0x00>;
			status = "okay";
			linux,phandle = <0x82>;
			phandle = <0x82>;

			port {
				#address-cells = <0x01>;
				#size-cells = <0x00>;

				endpoint@0 {
					reg = <0x00>;
					remote-endpoint = <0x40>;
					linux,phandle = <0x3b>;
					phandle = <0x3b>;
				};
			};
		};

		gpu@01c40000 {
			compatible = "arm,mali-400", "arm,mali-utgard";
			reg = <0x1c40000 0x10000>;
			interrupts = <0x45 0x46 0x47 0x48 0x49>;
			interrupt-names = "IRQGP", "IRQGPMMU", "IRQPP0", "IRQPPMMU0", "IRQPMU";
			clocks = <0x02 0x34 0x41>;
			clock-names = "ahb", "mod";
			resets = <0x41>;
			assigned-clocks = <0x41>;
			assigned-clock-rates = <0x1298be00>;
			linux,phandle = <0x83>;
			phandle = <0x83>;
		};
	};

	thermal-zones {

		cpu_thermal {
			polling-delay-passive = <0xfa>;
			polling-delay = <0x3e8>;
			thermal-sensors = <0x42>;

			cooling-maps {

				map0 {
					trip = <0x43>;
					cooling-device = <0x44 0xffffffff 0xffffffff>;
				};
			};

			trips {

				cpu_alert0 {
					temperature = <0xcf850>;
					hysteresis = <0x7d0>;
					type = "passive";
					linux,phandle = <0x43>;
					phandle = <0x43>;
				};

				cpu_crit {
					temperature = <0x186a0>;
					hysteresis = <0x7d0>;
					type = "critical";
					linux,phandle = <0x84>;
					phandle = <0x84>;
				};
			};
		};
	};

	display-engine {
		compatible = "allwinner,sun5i-a13-display-engine";
		allwinner,pipelines = <0x45>;
	};

	ahci-5v {
		compatible = "regulator-fixed";
		pinctrl-names = "default";
		pinctrl-0 = <0x46>;
		regulator-name = "ahci-5v";
		regulator-min-microvolt = <0x4c4b40>;
		regulator-max-microvolt = <0x4c4b40>;
		regulator-boot-on;
		enable-active-high;
		gpio = <0x2b 0x01 0x08 0x00>;
		status = "disabled";
		linux,phandle = <0x85>;
		phandle = <0x85>;
	};

	usb0-vbus {
		compatible = "regulator-fixed";
		pinctrl-names = "default";
		pinctrl-0 = <0x47>;
		regulator-name = "usb0-vbus";
		regulator-min-microvolt = <0x4c4b40>;
		regulator-max-microvolt = <0x4c4b40>;
		enable-active-high;
		gpio = <0x2b 0x01 0x0a 0x00>;
		status = "okay";
		vin-supply = <0x2e>;
		linux,phandle = <0x2d>;
		phandle = <0x2d>;
	};

	usb1-vbus {
		compatible = "regulator-fixed";
		pinctrl-names = "default";
		pinctrl-0 = <0x48>;
		regulator-name = "usb1-vbus";
		regulator-min-microvolt = <0x4c4b40>;
		regulator-max-microvolt = <0x4c4b40>;
		regulator-boot-on;
		enable-active-high;
		gpio = <0x2b 0x07 0x06 0x00>;
		status = "disabled";
		linux,phandle = <0x86>;
		phandle = <0x86>;
	};

	usb2-vbus {
		compatible = "regulator-fixed";
		pinctrl-names = "default";
		pinctrl-0 = <0x49>;
		regulator-name = "usb2-vbus";
		regulator-min-microvolt = <0x4c4b40>;
		regulator-max-microvolt = <0x4c4b40>;
		regulator-boot-on;
		enable-active-high;
		gpio = <0x2b 0x07 0x03 0x00>;
		status = "disabled";
		linux,phandle = <0x87>;
		phandle = <0x87>;
	};

	vcc3v0 {
		compatible = "regulator-fixed";
		regulator-name = "vcc3v0";
		regulator-min-microvolt = <0x2dc6c0>;
		regulator-max-microvolt = <0x2dc6c0>;
		linux,phandle = <0x31>;
		phandle = <0x31>;
	};

	vcc3v3 {
		compatible = "regulator-fixed";
		regulator-name = "vcc3v3";
		regulator-min-microvolt = <0x325aa0>;
		regulator-max-microvolt = <0x325aa0>;
		linux,phandle = <0x88>;
		phandle = <0x88>;
	};

	vcc5v0 {
		compatible = "regulator-fixed";
		regulator-name = "vcc5v0";
		regulator-min-microvolt = <0x4c4b40>;
		regulator-max-microvolt = <0x4c4b40>;
		linux,phandle = <0x2e>;
		phandle = <0x2e>;
	};

	leds {
		compatible = "gpio-leds";

		status {
			label = "chip:white:status";
			gpios = <0x4a 0x02 0x00>;
			default-state = "on";
			linux,default-trigger = "heartbeat";
			linux,phandle = <0x89>;
			phandle = <0x89>;
		};
	};

	mmc0_pwrseq {
		compatible = "mmc-pwrseq-simple";
		pinctrl-names = "default";
		pinctrl-0 = <0x4b>;
		reset-gpios = <0x2b 0x02 0x13 0x01>;
		linux,phandle = <0x24>;
		phandle = <0x24>;
	};

	onewire {
		compatible = "w1-gpio";
		gpios = <0x2b 0x03 0x02 0x00>;
		pinctrl-names = "default";
		pinctrl-0 = <0x4c>;
	};

	wifi_reg {
		compatible = "coupled-voltage-regulator";
		regulator-name = "vcc-wifi";
		vin0-supply = <0x4d>;
		vin1-supply = <0x4e>;
		linux,phandle = <0x23>;
		phandle = <0x23>;
	};

	__symbols__ {
		cpu0 = "/cpus/cpu@0";
		dummy = "/clocks/dummy";
		osc24M = "/clocks/clk@01c20050";
		osc3M = "/clocks/osc3M_clk";
		osc32k = "/clocks/clk@0";
		pll1 = "/clocks/clk@01c20000";
		pll2 = "/clocks/clk@01c20008";
		pll3 = "/clocks/clk@01c20010";
		pll3x2 = "/clocks/pll3x2_clk";
		pll4 = "/clocks/clk@01c20018";
		pll5 = "/clocks/clk@01c20020";
		pll6 = "/clocks/clk@01c20028";
		pll7 = "/clocks/clk@01c20030";
		pll7x2 = "/clocks/pll7x2_clk";
		cpu = "/clocks/cpu@01c20054";
		axi = "/clocks/axi@01c20054";
		ahb = "/clocks/ahb@01c20054";
		apb0 = "/clocks/apb0@01c20054";
		apb1 = "/clocks/clk@01c20058";
		axi_gates = "/clocks/clk@01c2005c";
		nand_clk = "/clocks/clk@01c20080";
		ms_clk = "/clocks/clk@01c20084";
		mmc0_clk = "/clocks/clk@01c20088";
		mmc1_clk = "/clocks/clk@01c2008c";
		mmc2_clk = "/clocks/clk@01c20090";
		ts_clk = "/clocks/clk@01c20098";
		ss_clk = "/clocks/clk@01c2009c";
		spi0_clk = "/clocks/clk@01c200a0";
		spi1_clk = "/clocks/clk@01c200a4";
		spi2_clk = "/clocks/clk@01c200a8";
		ir0_clk = "/clocks/clk@01c200b0";
		usb_clk = "/clocks/clk@01c200cc";
		codec_clk = "/clocks/clk@01c20140";
		mbus_clk = "/clocks/clk@01c2015c";
		ahb_gates = "/clocks/clk@01c20060";
		apb0_gates = "/clocks/clk@01c20068";
		apb1_gates = "/clocks/clk@01c2006c";
		dram_gates = "/clocks/clk@01c20100";
		de_be_clk = "/clocks/clk@01c20104";
		de_fe_clk = "/clocks/clk@01c2010c";
		tcon_ch0_clk = "/clocks/clk@01c20118";
		tcon_ch1_clk = "/clocks/clk@01c2012c";
		mali_clk = "/clocks/clk@01c20154";
		sram_a = "/soc@01c00000/sram-controller@01c00000/sram@00000000";
		sram_d = "/soc@01c00000/sram-controller@01c00000/sram@00010000";
		otg_sram = "/soc@01c00000/sram-controller@01c00000/sram@00010000/sram-section@0000";
		dma = "/soc@01c00000/dma-controller@01c02000";
		nfc = "/soc@01c00000/nand@01c03000";
		spi0 = "/soc@01c00000/spi@01c05000";
		spi1 = "/soc@01c00000/spi@01c06000";
		mmc0 = "/soc@01c00000/mmc@01c0f000";
		mmc1 = "/soc@01c00000/mmc@01c10000";
		mmc2 = "/soc@01c00000/mmc@01c11000";
		usb_otg = "/soc@01c00000/usb@01c13000";
		usbphy = "/soc@01c00000/phy@01c13400";
		ehci0 = "/soc@01c00000/usb@01c14000";
		ohci0 = "/soc@01c00000/usb@01c14400";
		spi2 = "/soc@01c00000/spi@01c17000";
		intc = "/soc@01c00000/interrupt-controller@01c20400";
		pio = "/soc@01c00000/pinctrl@01c20800";
		i2c0_pins_a = "/soc@01c00000/pinctrl@01c20800/i2c0@0";
		i2c1_pins_a = "/soc@01c00000/pinctrl@01c20800/i2c1@0";
		i2c2_pins_a = "/soc@01c00000/pinctrl@01c20800/i2c2@0";
		lcd_rgb565_pins = "/soc@01c00000/pinctrl@01c20800/lcd_rgb565@0";
		mmc0_pins_a = "/soc@01c00000/pinctrl@01c20800/mmc0@0";
		mmc2_pins_a = "/soc@01c00000/pinctrl@01c20800/mmc2@0";
		nand_pins_a = "/soc@01c00000/pinctrl@01c20800/nand_base0@0";
		nand_cs0_pins_a = "/soc@01c00000/pinctrl@01c20800/nand_cs@0";
		nand_cs1_pins_a = "/soc@01c00000/pinctrl@01c20800/nand_cs@1";
		nand_rb0_pins_a = "/soc@01c00000/pinctrl@01c20800/nand_rb@0";
		nand_rb1_pins_a = "/soc@01c00000/pinctrl@01c20800/nand_rb@1";
		spi2_pins_a = "/soc@01c00000/pinctrl@01c20800/spi2@0";
		spi2_cs0_pins_a = "/soc@01c00000/pinctrl@01c20800/spi2-cs0@0";
		uart3_pins_a = "/soc@01c00000/pinctrl@01c20800/uart3@0";
		uart3_pins_cts_rts_a = "/soc@01c00000/pinctrl@01c20800/uart3-cts-rts@0";
		pwm0_pins = "/soc@01c00000/pinctrl@01c20800/pwm0";
		lcd_rgb666_pins = "/soc@01c00000/pinctrl@01c20800/lcd_rgb666@0";
		uart1_pins_a = "/soc@01c00000/pinctrl@01c20800/uart1@0";
		uart1_pins_b = "/soc@01c00000/pinctrl@01c20800/uart1@1";
		ahci_pwr_pin_a = "/soc@01c00000/pinctrl@01c20800/ahci_pwr_pin@0";
		usb0_vbus_pin_a = "/soc@01c00000/pinctrl@01c20800/usb0_vbus_pin@0";
		usb1_vbus_pin_a = "/soc@01c00000/pinctrl@01c20800/usb1_vbus_pin@0";
		usb2_vbus_pin_a = "/soc@01c00000/pinctrl@01c20800/usb2_vbus_pin@0";
		chip_vbus_pin = "/soc@01c00000/pinctrl@01c20800/chip_vbus_pin@0";
		chip_wifi_reg_on_pin = "/soc@01c00000/pinctrl@01c20800/chip_wifi_reg_on_pin@0";
		chip_id_det_pin = "/soc@01c00000/pinctrl@01c20800/chip_id_det_pin@0";
		chip_w1_pin = "/soc@01c00000/pinctrl@01c20800/chip_w1_pin@0";
		wdt = "/soc@01c00000/watchdog@01c20c90";
		lradc = "/soc@01c00000/lradc@01c22800";
		codec = "/soc@01c00000/codec@01c22c00";
		sid = "/soc@01c00000/eeprom@01c23800";
		rtp = "/soc@01c00000/rtp@01c25000";
		uart1 = "/soc@01c00000/serial@01c28400";
		uart3 = "/soc@01c00000/serial@01c28c00";
		i2c0 = "/soc@01c00000/i2c@01c2ac00";
		axp209 = "/soc@01c00000/i2c@01c2ac00/pmic@34";
		axp_gpio = "/soc@01c00000/i2c@01c2ac00/pmic@34/gpio";
		reg_dcdc2 = "/soc@01c00000/i2c@01c2ac00/pmic@34/regulators/dcdc2";
		reg_dcdc3 = "/soc@01c00000/i2c@01c2ac00/pmic@34/regulators/dcdc3";
		reg_ldo1 = "/soc@01c00000/i2c@01c2ac00/pmic@34/regulators/ldo1";
		reg_ldo2 = "/soc@01c00000/i2c@01c2ac00/pmic@34/regulators/ldo2";
		reg_ldo3 = "/soc@01c00000/i2c@01c2ac00/pmic@34/regulators/ldo3";
		reg_ldo4 = "/soc@01c00000/i2c@01c2ac00/pmic@34/regulators/ldo4";
		reg_ldo5 = "/soc@01c00000/i2c@01c2ac00/pmic@34/regulators/ldo5";
		usb_power_supply = "/soc@01c00000/i2c@01c2ac00/pmic@34/usb_power_supply";
		i2c1 = "/soc@01c00000/i2c@01c2b000";
		i2c2 = "/soc@01c00000/i2c@01c2b400";
		xio = "/soc@01c00000/i2c@01c2b400/gpio@38";
		tcon0 = "/soc@01c00000/lcd-controller@01c0c000";
		tcon0_in = "/soc@01c00000/lcd-controller@01c0c000/ports/port@0";
		tcon0_in_be0 = "/soc@01c00000/lcd-controller@01c0c000/ports/port@0/endpoint@0";
		tcon0_out = "/soc@01c00000/lcd-controller@01c0c000/ports/port@1";
		tcon0_out_tve0 = "/soc@01c00000/lcd-controller@01c0c000/ports/port@1/endpoint@1";
		pwm = "/soc@01c00000/pwm@01c20e00";
		fe0 = "/soc@01c00000/display-frontend@01e00000";
		fe0_out = "/soc@01c00000/display-frontend@01e00000/ports/port@1";
		fe0_out_be0 = "/soc@01c00000/display-frontend@01e00000/ports/port@1/endpoint@0";
		be0 = "/soc@01c00000/display-backend@01e60000";
		be0_in = "/soc@01c00000/display-backend@01e60000/ports/port@0";
		be0_in_fe0 = "/soc@01c00000/display-backend@01e60000/ports/port@0/endpoint@0";
		be0_out = "/soc@01c00000/display-backend@01e60000/ports/port@1";
		be0_out_tcon0 = "/soc@01c00000/display-backend@01e60000/ports/port@1/endpoint@0";
		tve0 = "/soc@01c00000/tv-encoder@01c0a000";
		tve0_in_tcon0 = "/soc@01c00000/tv-encoder@01c0a000/port/endpoint@0";
		mali = "/soc@01c00000/gpu@01c40000";
		cpu_alert0 = "/thermal-zones/cpu_thermal/trips/cpu_alert0";
		cpu_crit = "/thermal-zones/cpu_thermal/trips/cpu_crit";
		reg_ahci_5v = "/ahci-5v";
		reg_usb0_vbus = "/usb0-vbus";
		reg_usb1_vbus = "/usb1-vbus";
		reg_usb2_vbus = "/usb2-vbus";
		reg_vcc3v0 = "/vcc3v0";
		reg_vcc3v3 = "/vcc3v3";
		reg_vcc5v0 = "/vcc5v0";
		leds_status = "/leds/status";
		mmc0_pwrseq = "/mmc0_pwrseq";
		vcc_wifi = "/wifi_reg";
	};

	__local_fixups__ {
		interrupt-parent = <0x00>;

		chosen {

			framebuffer@0 {
				clocks = <0x00 0x08 0x10 0x14 0x18>;
			};

			framebuffer@1 {
				clocks = <0x00 0x08 0x10 0x18 0x1c 0x20>;
			};
		};

		cpus {

			cpu@0 {
				clocks = <0x00>;
				cpu-supply = <0x00>;
			};
		};

		clocks {

			osc3M_clk {
				clocks = <0x00>;
			};

			clk@01c20000 {
				clocks = <0x00>;
			};

			clk@01c20008 {
				clocks = <0x00>;
			};

			clk@01c20010 {
				clocks = <0x00>;
			};

			pll3x2_clk {
				clocks = <0x00>;
			};

			clk@01c20018 {
				clocks = <0x00>;
			};

			clk@01c20020 {
				clocks = <0x00>;
			};

			clk@01c20028 {
				clocks = <0x00>;
			};

			clk@01c20030 {
				clocks = <0x00>;
			};

			pll7x2_clk {
				clocks = <0x00>;
			};

			cpu@01c20054 {
				clocks = <0x00 0x04 0x08 0x0c>;
			};

			axi@01c20054 {
				clocks = <0x00>;
			};

			ahb@01c20054 {
				clocks = <0x00 0x04 0x08>;
				assigned-clocks = <0x00>;
				assigned-clock-parents = <0x00>;
			};

			apb0@01c20054 {
				clocks = <0x00>;
			};

			clk@01c20058 {
				clocks = <0x00 0x04 0x0c>;
			};

			clk@01c2005c {
				clocks = <0x00>;
			};

			clk@01c20080 {
				clocks = <0x00 0x04 0x0c>;
			};

			clk@01c20084 {
				clocks = <0x00 0x04 0x0c>;
			};

			clk@01c20088 {
				clocks = <0x00 0x04 0x0c>;
			};

			clk@01c2008c {
				clocks = <0x00 0x04 0x0c>;
			};

			clk@01c20090 {
				clocks = <0x00 0x04 0x0c>;
			};

			clk@01c20098 {
				clocks = <0x00 0x04 0x0c>;
			};

			clk@01c2009c {
				clocks = <0x00 0x04 0x0c>;
			};

			clk@01c200a0 {
				clocks = <0x00 0x04 0x0c>;
			};

			clk@01c200a4 {
				clocks = <0x00 0x04 0x0c>;
			};

			clk@01c200a8 {
				clocks = <0x00 0x04 0x0c>;
			};

			clk@01c200b0 {
				clocks = <0x00 0x04 0x0c>;
			};

			clk@01c200cc {
				clocks = <0x00>;
			};

			clk@01c20140 {
				clocks = <0x00>;
			};

			clk@01c2015c {
				clocks = <0x00 0x04 0x0c>;
			};

			clk@01c20060 {
				clocks = <0x00>;
			};

			clk@01c20068 {
				clocks = <0x00>;
			};

			clk@01c2006c {
				clocks = <0x00>;
			};

			clk@01c20100 {
				clocks = <0x00>;
			};

			clk@01c20104 {
				clocks = <0x00 0x04 0x08>;
			};

			clk@01c2010c {
				clocks = <0x00 0x04 0x08>;
			};

			clk@01c20118 {
				clocks = <0x00 0x04 0x08 0x0c>;
			};

			clk@01c2012c {
				clocks = <0x00 0x04 0x08 0x0c>;
			};

			clk@01c20154 {
				clocks = <0x00 0x04 0x08 0x10 0x14>;
			};
		};

		soc@01c00000 {

			dma-controller@01c02000 {
				clocks = <0x00>;
			};

			nand@01c03000 {
				clocks = <0x00 0x08>;
				pinctrl-0 = <0x00 0x04 0x08>;
				dmas = <0x00>;
			};

			spi@01c05000 {
				clocks = <0x00 0x08>;
				dmas = <0x00 0x0c>;
			};

			spi@01c06000 {
				clocks = <0x00 0x08>;
				dmas = <0x00 0x0c>;
			};

			mmc@01c0f000 {
				clocks = <0x00 0x08 0x10 0x18>;
				pinctrl-0 = <0x00>;
				vmmc-supply = <0x00>;
				mmc-pwrseq = <0x00>;
			};

			mmc@01c10000 {
				clocks = <0x00 0x08 0x10 0x18>;
			};

			mmc@01c11000 {
				clocks = <0x00 0x08 0x10 0x18>;
			};

			usb@01c13000 {
				clocks = <0x00>;
				phys = <0x00>;
				extcon = <0x00>;
				allwinner,sram = <0x00>;
			};

			phy@01c13400 {
				clocks = <0x00>;
				resets = <0x00 0x08>;
				pinctrl-0 = <0x00>;
				usb0_id_det-gpio = <0x00>;
				usb0_vbus_power-supply = <0x00>;
				usb0_vbus-supply = <0x00>;
				usb1_vbus-supply = <0x00>;
			};

			usb@01c14000 {
				clocks = <0x00>;
				phys = <0x00>;
			};

			usb@01c14400 {
				clocks = <0x00 0x08>;
				phys = <0x00>;
			};

			spi@01c17000 {
				clocks = <0x00 0x08>;
				dmas = <0x00 0x0c>;
			};

			pinctrl@01c20800 {
				clocks = <0x00>;
			};

			timer@01c20c00 {
				clocks = <0x00>;
			};

			lradc@01c22800 {
				vref-supply = <0x00>;
			};

			codec@01c22c00 {
				clocks = <0x00 0x08>;
				dmas = <0x00 0x0c>;
			};

			serial@01c28400 {
				clocks = <0x00>;
				pinctrl-0 = <0x00>;
			};

			serial@01c28c00 {
				clocks = <0x00>;
				pinctrl-0 = <0x00 0x04>;
			};

			i2c@01c2ac00 {
				clocks = <0x00>;
				pinctrl-0 = <0x00>;
			};

			i2c@01c2b000 {
				clocks = <0x00>;
				pinctrl-0 = <0x00>;
			};

			i2c@01c2b400 {
				clocks = <0x00>;
				pinctrl-0 = <0x00>;

				gpio@38 {
					interrupt-parent = <0x00>;
				};
			};

			timer@01c60000 {
				clocks = <0x00>;
			};

			lcd-controller@01c0c000 {
				resets = <0x00>;
				clocks = <0x00 0x08 0x0c>;

				ports {

					port@0 {

						endpoint@0 {
							remote-endpoint = <0x00>;
						};
					};

					port@1 {

						endpoint@1 {
							remote-endpoint = <0x00>;
						};
					};
				};
			};

			pwm@01c20e00 {
				clocks = <0x00>;
			};

			display-frontend@01e00000 {
				clocks = <0x00 0x08 0x0c>;
				resets = <0x00>;

				ports {

					port@1 {

						endpoint@0 {
							remote-endpoint = <0x00>;
						};
					};
				};
			};

			display-backend@01e60000 {
				clocks = <0x00 0x08 0x0c>;
				resets = <0x00>;
				assigned-clocks = <0x00>;

				ports {

					port@0 {

						endpoint@0 {
							remote-endpoint = <0x00>;
						};
					};

					port@1 {

						endpoint@0 {
							remote-endpoint = <0x00>;
						};
					};
				};
			};

			tv-encoder@01c0a000 {
				clocks = <0x00>;
				resets = <0x00>;

				port {

					endpoint@0 {
						remote-endpoint = <0x00>;
					};
				};
			};

			gpu@01c40000 {
				clocks = <0x00 0x08>;
				resets = <0x00>;
				assigned-clocks = <0x00>;
			};
		};

		thermal-zones {

			cpu_thermal {
				thermal-sensors = <0x00>;

				cooling-maps {

					map0 {
						trip = <0x00>;
						cooling-device = <0x00>;
					};
				};
			};
		};

		display-engine {
			allwinner,pipelines = <0x00>;
		};

		ahci-5v {
			pinctrl-0 = <0x00>;
			gpio = <0x00>;
		};

		usb0-vbus {
			pinctrl-0 = <0x00>;
			gpio = <0x00>;
			vin-supply = <0x00>;
		};

		usb1-vbus {
			pinctrl-0 = <0x00>;
			gpio = <0x00>;
		};

		usb2-vbus {
			pinctrl-0 = <0x00>;
			gpio = <0x00>;
		};

		leds {

			status {
				gpios = <0x00>;
			};
		};

		mmc0_pwrseq {
			pinctrl-0 = <0x00>;
			reset-gpios = <0x00>;
		};

		onewire {
			gpios = <0x00>;
			pinctrl-0 = <0x00>;
		};

		wifi_reg {
			vin0-supply = <0x00>;
			vin1-supply = <0x00>;
		};
	};
};
